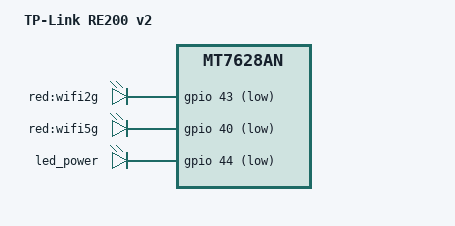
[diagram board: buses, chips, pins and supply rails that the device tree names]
// SPDX-License-Identifier: GPL-2.0-or-later OR MIT

#include "mt7628an_tplink_re200.dtsi"

/ {
	compatible = "tplink,re200-v2", "mediatek,mt7628an-soc";
	model = "TP-Link RE200 v2";

	leds {
		wifi2g_red {
			label = "red:wifi2g";
			gpios = <&gpio 43 GPIO_ACTIVE_LOW>;
		};

		wifi5g_red {
			label = "red:wifi5g";
			gpios = <&gpio 40 GPIO_ACTIVE_LOW>;
		};
	};
};

&led_power {
	gpios = <&gpio 44 GPIO_ACTIVE_LOW>;
};
